# STM32L021K4U6 register map
File version: 1.0
Registers are 32-bit, access not given, reset 0x0 unless marked. A register's access mark holds for its fields unless they carry their own. Offsets are from the block's base; [hi:lo] are bit positions; {n}, {i} and the like mark numbered series.

## I2C1
Base 0x40005400
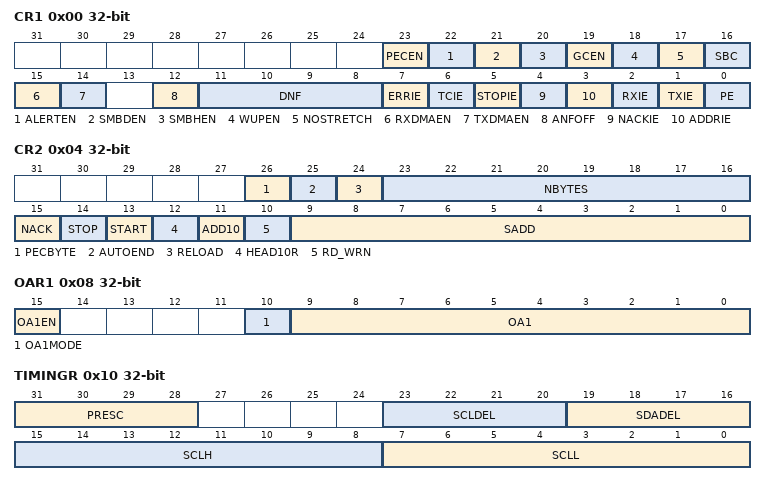
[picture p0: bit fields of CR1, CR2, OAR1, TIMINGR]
0x00 CR1
  [23] PECEN, [22] ALERTEN, [21] SMBDEN, [20] SMBHEN, [19] GCEN, [18] WUPEN, [17] NOSTRETCH, [16] SBC, [15] RXDMAEN, [14] TXDMAEN, [12] ANFOFF, [11:8] DNF, [7] ERRIE, [6] TCIE, [5] STOPIE, [4] NACKIE, [3] ADDRIE, [2] RXIE, [1] TXIE, [0] PE
0x04 CR2
  [26] PECBYTE, [25] AUTOEND, [24] RELOAD, [23:16] NBYTES, [15] NACK, [14] STOP, [13] START, [12] HEAD10R, [11] ADD10, [10] RD_WRN, [9:0] SADD
0x08 OAR1
  [15] OA1EN, [10] OA1MODE, [9:0] OA1
0x0C OAR2
  [15] OA2EN, [10] OA2MASK04, [10:9] OA2MASK06, [10:8] OA2MSK, [7:1] OA2
0x10 TIMINGR
  [31:28] PRESC, [23:20] SCLDEL, [19:16] SDADEL, [15:8] SCLH, [7:0] SCLL
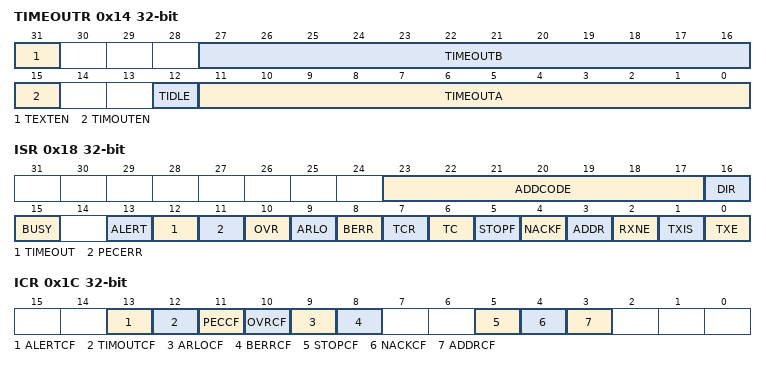
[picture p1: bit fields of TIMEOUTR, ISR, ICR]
0x14 TIMEOUTR
  [31] TEXTEN, [27:16] TIMEOUTB, [15] TIMOUTEN, [12] TIDLE, [11:0] TIMEOUTA
0x18 ISR
  [23:17] ADDCODE, [16] DIR, [15] BUSY, [13] ALERT, [12] TIMEOUT, [11] PECERR, [10] OVR, [9] ARLO, [8] BERR, [7] TCR, [6] TC, [5] STOPF, [4] NACKF, [3] ADDR, [2] RXNE, [1] TXIS, [0] TXE
0x1C ICR
  [13] ALERTCF, [12] TIMOUTCF, [11] PECCF, [10] OVRCF, [9] ARLOCF, [8] BERRCF, [5] STOPCF, [4] NACKCF, [3] ADDRCF
0x20 PECR
  [7:0] PEC
0x24 RXDR
  [7:0] RXDATA
0x28 TXDR
  [7:0] TXDATA

## PWR
Base 0x40007000
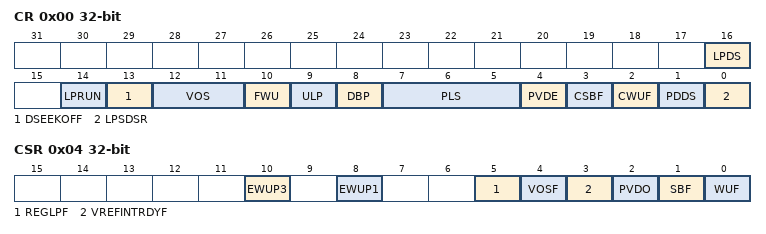
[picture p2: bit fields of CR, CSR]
0x00 CR
  [16] LPDS, [14] LPRUN, [13] DSEEKOFF, [12:11] VOS, [10] FWU, [9] ULP, [8] DBP, [7:5] PLS, [4] PVDE, [3] CSBF, [2] CWUF, [1] PDDS, [0] LPSDSR
0x04 CSR
  [10] EWUP3, [8] EWUP1, [5] REGLPF, [4] VOSF, [3] VREFINTRDYF, [2] PVDO, [1] SBF, [0] WUF

## LPTIM1
Base 0x40007C00
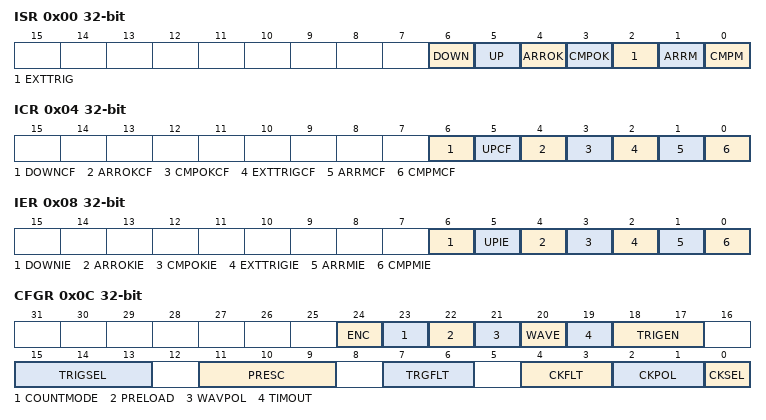
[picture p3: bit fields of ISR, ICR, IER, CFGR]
0x00 ISR
  [6] DOWN, [5] UP, [4] ARROK, [3] CMPOK, [2] EXTTRIG, [1] ARRM, [0] CMPM
0x04 ICR
  [6] DOWNCF, [5] UPCF, [4] ARROKCF, [3] CMPOKCF, [2] EXTTRIGCF, [1] ARRMCF, [0] CMPMCF
0x08 IER
  [6] DOWNIE, [5] UPIE, [4] ARROKIE, [3] CMPOKIE, [2] EXTTRIGIE, [1] ARRMIE, [0] CMPMIE
0x0C CFGR
  [24] ENC, [23] COUNTMODE, [22] PRELOAD, [21] WAVPOL, [20] WAVE, [19] TIMOUT, [18:17] TRIGEN, [15:13] TRIGSEL, [11:9] PRESC, [7:6] TRGFLT, [4:3] CKFLT, [2:1] CKPOL, [0] CKSEL
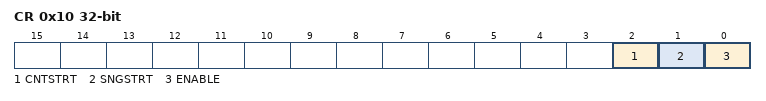
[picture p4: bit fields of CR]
0x10 CR
  [2] CNTSTRT, [1] SNGSTRT, [0] ENABLE
0x14 CMP
  [15:0] CMP
0x18 ARR
  [15:0] ARR
0x1C CNT
  [15:0] CNT

## SYSCFG
Base 0x40010000
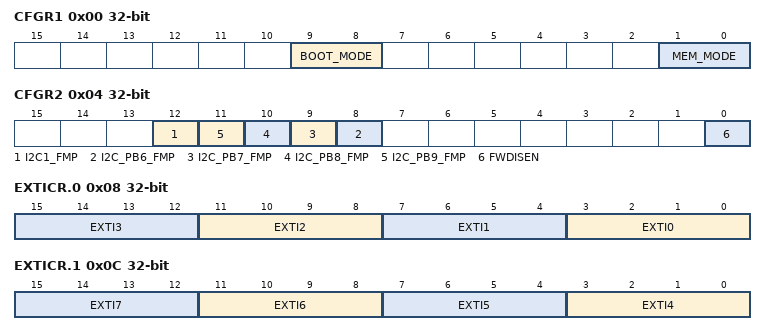
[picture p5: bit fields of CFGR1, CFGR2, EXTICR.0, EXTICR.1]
0x00 CFGR1
  [9:8] BOOT_MODE, [1:0] MEM_MODE
0x04 CFGR2
  [12] I2C1_FMP, [n+2] I2C_PB{n}_FMP (n=6..9), [0] FWDISEN
0x08 EXTICR.0
  [4n+3:4n] EXTI{n} (n=0..3)
0x0C EXTICR.1
  [4n-13:4n-16] EXTI{n} (n=4..7)
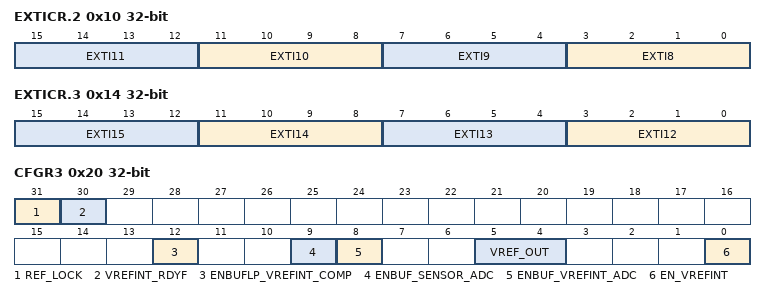
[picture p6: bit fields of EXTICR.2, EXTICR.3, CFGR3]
0x10 EXTICR.2
  [4n-29:4n-32] EXTI{n} (n=8..11)
0x14 EXTICR.3
  [4n-45:4n-48] EXTI{n} (n=12..15)
0x20 CFGR3
  [31] REF_LOCK, [30] VREFINT_RDYF, [12] ENBUFLP_VREFINT_COMP, [9] ENBUF_SENSOR_ADC, [8] ENBUF_VREFINT_ADC, [5:4] VREF_OUT, [0] EN_VREFINT

## COMP12_COMMON
Base 0x40010018
Same registers: COMP1 0x40010018
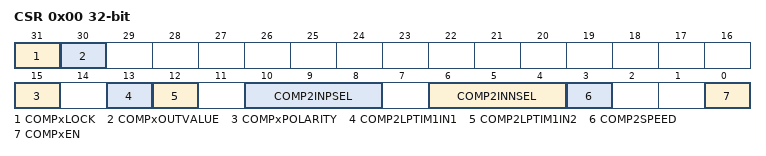
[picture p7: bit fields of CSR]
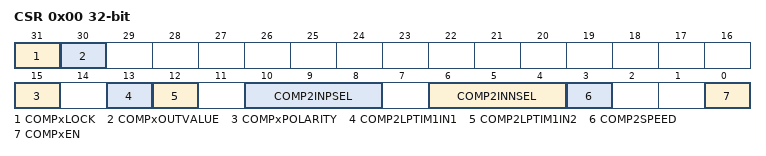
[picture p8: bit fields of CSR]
0x00 CSR
  [31] COMPxLOCK, [30] COMPxOUTVALUE, [15] COMPxPOLARITY, [13] COMP2LPTIM1IN1, [12] COMP2LPTIM1IN2, [10:8] COMP2INPSEL, [6:4] COMP2INNSEL, [3] COMP2SPEED, [0] COMPxEN

## COMP2
Base 0x4001001C
0x00 CSR
  [31] COMPxLOCK, [30] COMPxOUTVALUE, [15] COMPxPOLARITY, [13] COMP2LPTIM1IN1, [12] COMP2LPTIM1IN2, [10:8] COMP2INPSEL, [6:4] COMP2INNSEL, [3] COMP2SPEED, [0] COMPxEN

## EXTI
Base 0x40010400
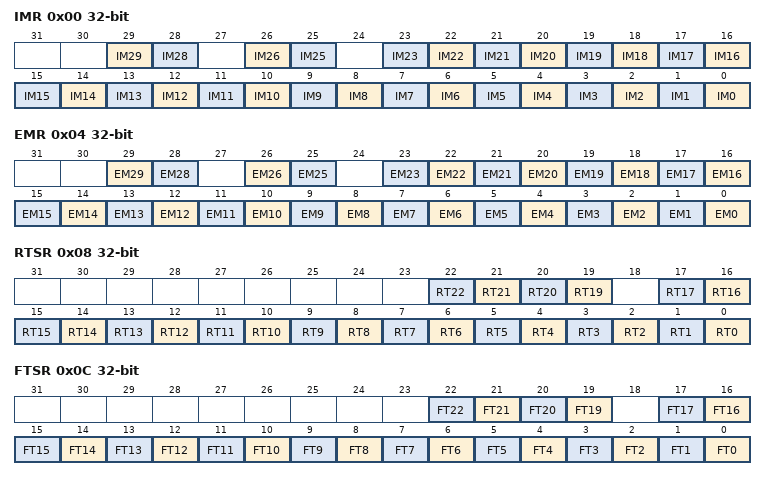
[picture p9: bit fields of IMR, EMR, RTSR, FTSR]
0x00 IMR
  [29] IM29, [28] IM28, [26] IM26, [25] IM25, [n] IM{n} (n=0..23)
0x04 EMR
  [29] EM29, [28] EM28, [26] EM26, [25] EM25, [n] EM{n} (n=0..23)
0x08 RTSR
  [n] RT{n} (n=19..22), [n] RT{n} (n=0..17)
0x0C FTSR
  [n] FT{n} (n=19..22), [n] FT{n} (n=0..17)
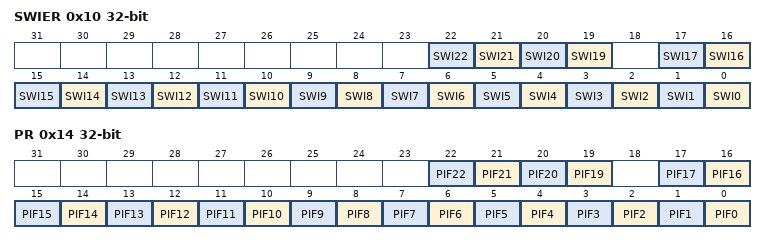
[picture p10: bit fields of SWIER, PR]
0x10 SWIER
  [n] SWI{n} (n=19..22), [n] SWI{n} (n=0..17)
0x14 PR
  [n] PIF{n} (n=19..22), [n] PIF{n} (n=0..17)

## ADC1
Base 0x40012400
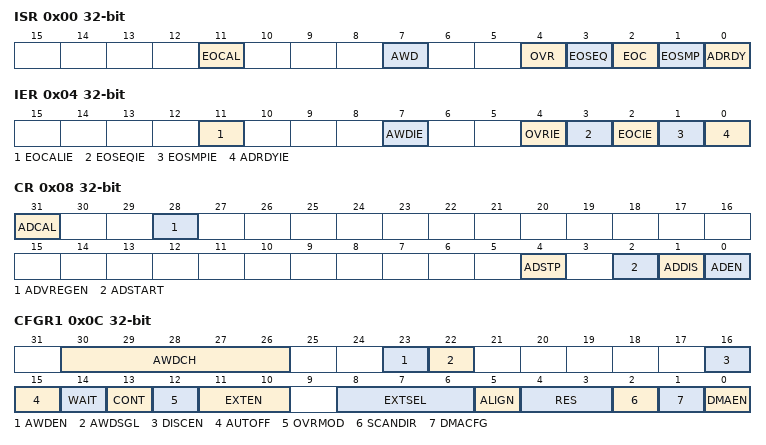
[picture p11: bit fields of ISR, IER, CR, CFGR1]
0x00 ISR
  [11] EOCAL, [7] AWD, [4] OVR, [3] EOSEQ, [2] EOC, [1] EOSMP, [0] ADRDY
0x04 IER
  [11] EOCALIE, [7] AWDIE, [4] OVRIE, [3] EOSEQIE, [2] EOCIE, [1] EOSMPIE, [0] ADRDYIE
0x08 CR
  [31] ADCAL, [28] ADVREGEN, [4] ADSTP, [2] ADSTART, [1] ADDIS, [0] ADEN
0x0C CFGR1
  [30:26] AWDCH, [23] AWDEN, [22] AWDSGL, [16] DISCEN, [15] AUTOFF, [14] WAIT, [13] CONT, [12] OVRMOD, [11:10] EXTEN, [8:6] EXTSEL, [5] ALIGN, [4:3] RES, [2] SCANDIR, [1] DMACFG, [0] DMAEN
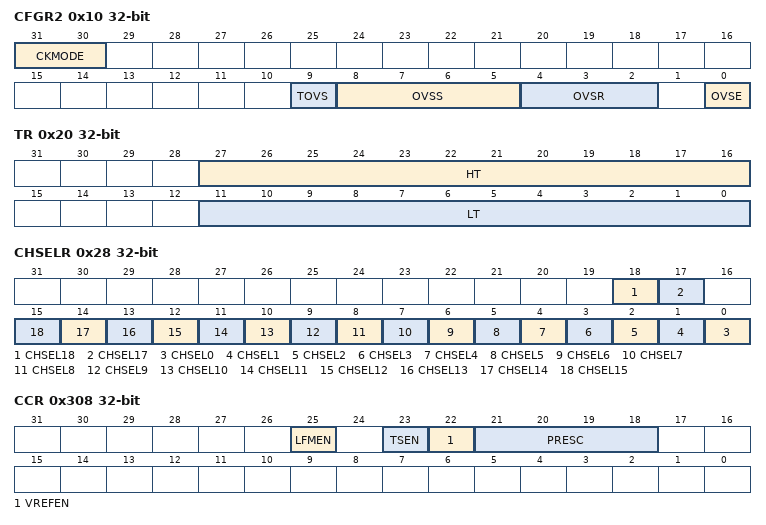
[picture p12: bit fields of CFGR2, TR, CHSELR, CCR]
0x10 CFGR2
  [31:30] CKMODE, [9] TOVS, [8:5] OVSS, [4:2] OVSR, [0] OVSE
0x14 SMPR
  [2:0] SMP
0x20 TR
  [27:16] HT, [11:0] LT
0x28 CHSELR
  [18] CHSEL18, [17] CHSEL17, [n] CHSEL{n} (n=0..15)
0x40 DR
  [15:0] DATA
0xB4 CALFACT
  [6:0] CALFACT
0x308 CCR
  [25] LFMEN, [23] TSEN, [22] VREFEN, [21:18] PRESC
